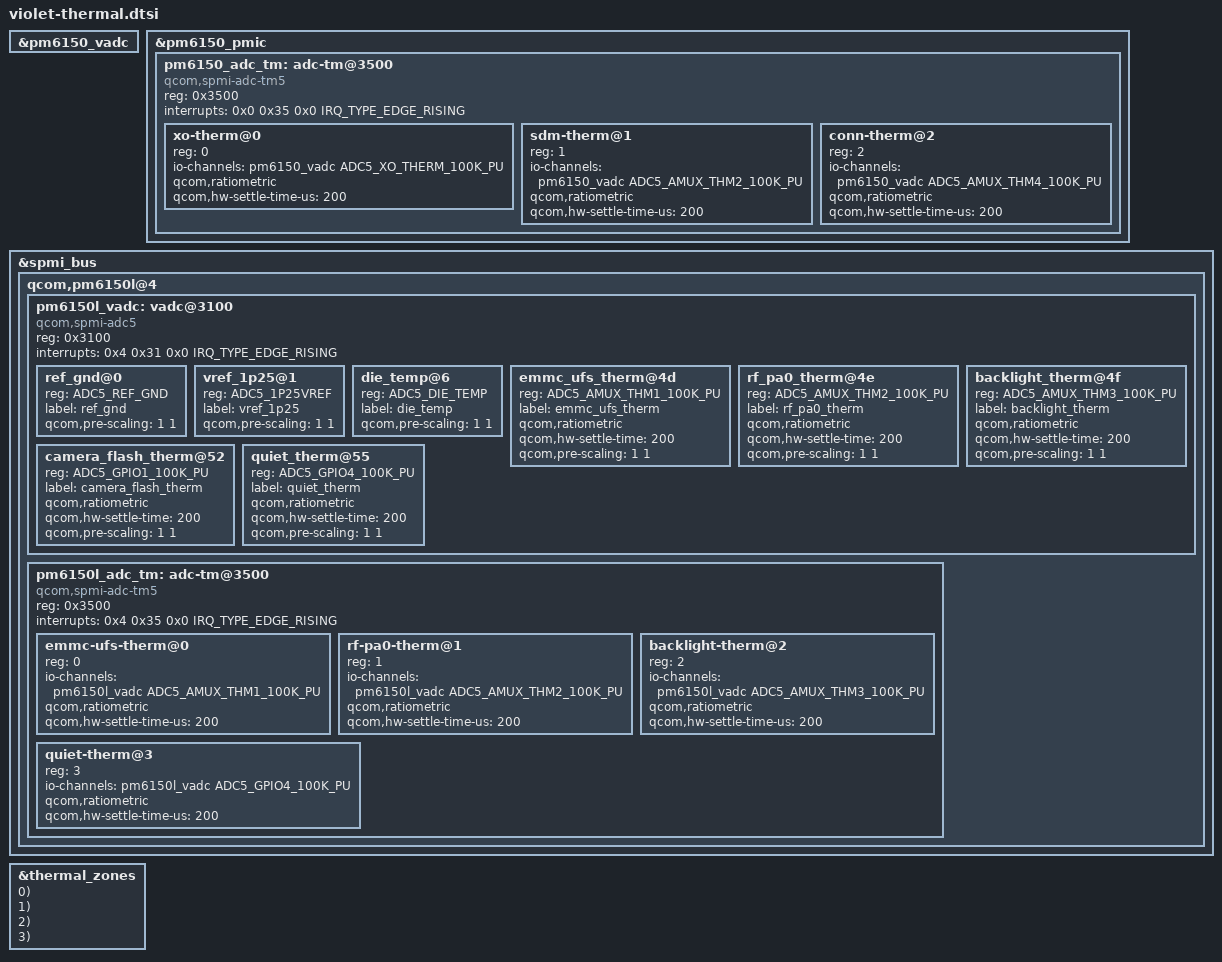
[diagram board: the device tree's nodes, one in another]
// SPDX-License-Identifier: GPL-2.0-only
/*
 * violet board thermistors as thermal zones, for the vendor thermal-engine:
 * it mitigates CPU frequency on sdm-therm (skin), battery charging on
 * quiet-therm and the backlight on backlight_therm, and finds the zones by
 * name. Channels and zone names are those of the 4.14 sm6150-thermal.dtsi
 * and violet-sm6150-thermal.dtsi: backlight_therm on pm6150l AMUX THM3
 * instead of rf_pa1, and no camera flash thermal monitor channel.
 * All are 100k pull-up NTCs read ratiometrically; ADC-TM5 serves the
 * temperatures and threshold interrupts.
 */
#include <dt-bindings/iio/qcom,spmi-vadc.h>
#include <dt-bindings/interrupt-controller/irq.h>
#include <dt-bindings/spmi/spmi.h>

&pm6150_vadc {
	#io-channel-cells = <1>;
};

&pm6150_pmic {
	pm6150_adc_tm: adc-tm@3500 {
		compatible = "qcom,spmi-adc-tm5";
		reg = <0x3500>;
		interrupts = <0x0 0x35 0x0 IRQ_TYPE_EDGE_RISING>;
		#address-cells = <1>;
		#size-cells = <0>;
		#thermal-sensor-cells = <1>;

		xo-therm@0 {
			reg = <0>;
			io-channels = <&pm6150_vadc ADC5_XO_THERM_100K_PU>;
			qcom,ratiometric;
			qcom,hw-settle-time-us = <200>;
		};

		sdm-therm@1 {
			reg = <1>;
			io-channels = <&pm6150_vadc ADC5_AMUX_THM2_100K_PU>;
			qcom,ratiometric;
			qcom,hw-settle-time-us = <200>;
		};

		conn-therm@2 {
			reg = <2>;
			io-channels = <&pm6150_vadc ADC5_AMUX_THM4_100K_PU>;
			qcom,ratiometric;
			qcom,hw-settle-time-us = <200>;
		};
	};
};

&spmi_bus {
	qcom,pm6150l@4 {
		pm6150l_vadc: vadc@3100 {
			compatible = "qcom,spmi-adc5";
			reg = <0x3100>;
			#address-cells = <1>;
			#size-cells = <0>;
			interrupts = <0x4 0x31 0x0 IRQ_TYPE_EDGE_RISING>;
			interrupt-names = "eoc-int-en-set";
			#io-channel-cells = <1>;

			ref_gnd@0 {
				reg = <ADC5_REF_GND>;
				label = "ref_gnd";
				qcom,pre-scaling = <1 1>;
			};

			vref_1p25@1 {
				reg = <ADC5_1P25VREF>;
				label = "vref_1p25";
				qcom,pre-scaling = <1 1>;
			};

			die_temp@6 {
				reg = <ADC5_DIE_TEMP>;
				label = "die_temp";
				qcom,pre-scaling = <1 1>;
			};

			emmc_ufs_therm@4d {
				reg = <ADC5_AMUX_THM1_100K_PU>;
				label = "emmc_ufs_therm";
				qcom,ratiometric;
				qcom,hw-settle-time = <200>;
				qcom,pre-scaling = <1 1>;
			};

			rf_pa0_therm@4e {
				reg = <ADC5_AMUX_THM2_100K_PU>;
				label = "rf_pa0_therm";
				qcom,ratiometric;
				qcom,hw-settle-time = <200>;
				qcom,pre-scaling = <1 1>;
			};

			backlight_therm@4f {
				reg = <ADC5_AMUX_THM3_100K_PU>;
				label = "backlight_therm";
				qcom,ratiometric;
				qcom,hw-settle-time = <200>;
				qcom,pre-scaling = <1 1>;
			};

			camera_flash_therm@52 {
				reg = <ADC5_GPIO1_100K_PU>;
				label = "camera_flash_therm";
				qcom,ratiometric;
				qcom,hw-settle-time = <200>;
				qcom,pre-scaling = <1 1>;
			};

			quiet_therm@55 {
				reg = <ADC5_GPIO4_100K_PU>;
				label = "quiet_therm";
				qcom,ratiometric;
				qcom,hw-settle-time = <200>;
				qcom,pre-scaling = <1 1>;
			};
		};

		pm6150l_adc_tm: adc-tm@3500 {
			compatible = "qcom,spmi-adc-tm5";
			reg = <0x3500>;
			interrupts = <0x4 0x35 0x0 IRQ_TYPE_EDGE_RISING>;
			#address-cells = <1>;
			#size-cells = <0>;
			#thermal-sensor-cells = <1>;

			emmc-ufs-therm@0 {
				reg = <0>;
				io-channels = <&pm6150l_vadc ADC5_AMUX_THM1_100K_PU>;
				qcom,ratiometric;
				qcom,hw-settle-time-us = <200>;
			};

			rf-pa0-therm@1 {
				reg = <1>;
				io-channels = <&pm6150l_vadc ADC5_AMUX_THM2_100K_PU>;
				qcom,ratiometric;
				qcom,hw-settle-time-us = <200>;
			};

			backlight-therm@2 {
				reg = <2>;
				io-channels = <&pm6150l_vadc ADC5_AMUX_THM3_100K_PU>;
				qcom,ratiometric;
				qcom,hw-settle-time-us = <200>;
			};

			quiet-therm@3 {
				reg = <3>;
				io-channels = <&pm6150l_vadc ADC5_GPIO4_100K_PU>;
				qcom,ratiometric;
				qcom,hw-settle-time-us = <200>;
			};
		};
	};
};

#define VIOLET_THERM_ZONE(sensor, chan)					\
	{								\
		polling-delay-passive = <0>;				\
		polling-delay = <0>;					\
		thermal-sensors = <&sensor chan>;			\
		trips {							\
			active-config0 {				\
				temperature = <125000>;			\
				hysteresis = <1000>;			\
				type = "passive";			\
			};						\
		};							\
	}

&thermal_zones {
	xo-therm VIOLET_THERM_ZONE(pm6150_adc_tm, 0);
	sdm-therm VIOLET_THERM_ZONE(pm6150_adc_tm, 1);
	conn-therm VIOLET_THERM_ZONE(pm6150_adc_tm, 2);
	emmc_ufs-therm VIOLET_THERM_ZONE(pm6150l_adc_tm, 0);
	rf_pa0_therm-therm VIOLET_THERM_ZONE(pm6150l_adc_tm, 1);
	backlight_therm VIOLET_THERM_ZONE(pm6150l_adc_tm, 2);
	quiet-therm VIOLET_THERM_ZONE(pm6150l_adc_tm, 3);
};
